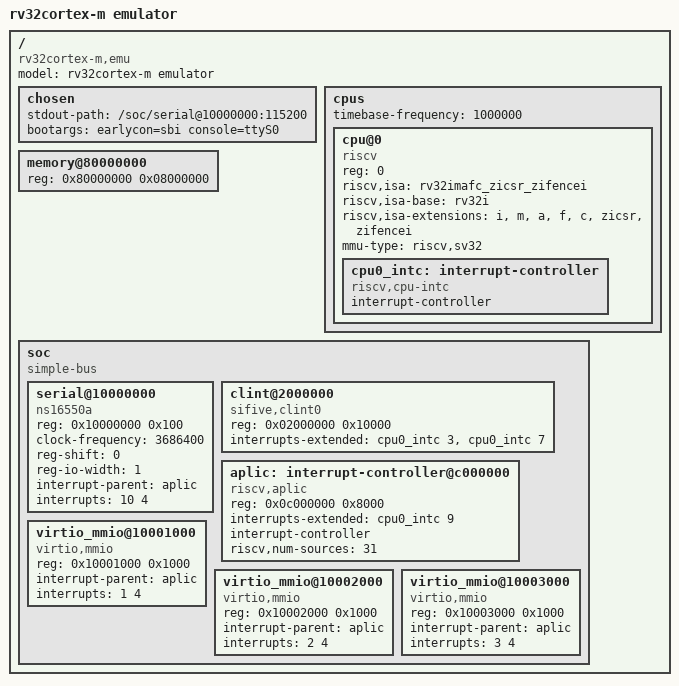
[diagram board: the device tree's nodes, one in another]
/dts-v1/;

/*
 * The machine this emulator presents to a supervisor payload.
 *
 * Why there is a device tree at all
 * --------------------------------
 * Every guest in this tree until now was compiled for these addresses.
 * OpenSBI and Linux are not: they are built once and told the shape of
 * the machine at boot, through a flattened tree whose address arrives in
 * a1. So this file *is* the machine description, and anything here that
 * disagrees with `include/emu/emu_memmap.h` or `include/rv32/rv_memmap.h`
 * is a bug that presents as firmware hanging with no output.
 *
 * The addresses are deliberately the QEMU `virt` ones, which is what the
 * emulator already chose independently: CLINT at 0x0200_0000, an
 * NS16550 at 0x1000_0000, RAM at 0x8000_0000. That means OpenSBI's
 * `generic` platform and an ordinary `rv32_defconfig` Linux need no
 * board support -- they read this and find a machine they know.
 *
 * Build it with:
 *   dtc -I dts -O dtb -o rv32-emu.dtb boot/rv32-emu.dts
 */

/ {
    #address-cells = <1>;
    #size-cells = <1>;
    compatible = "rv32cortex-m,emu";
    model = "rv32cortex-m emulator";

    chosen {
        /*
         * `stdout-path` is how OpenSBI and Linux find the console when
         * they are not told on the command line. Without it OpenSBI
         * comes up, works, and prints nothing -- which is
         * indistinguishable from not booting.
         */
        stdout-path = "/soc/serial@10000000:115200";
        /*
         * **The console goes through SBI, not the UART, and that is
         * deliberate for the first boot.**
         *
         * `earlycon=sbi` and `console=hvc0` are ecalls into OpenSBI,
         * which is already proven to reach this machine's NS16550. They
         * need no MMIO mapping, no interrupt and no PLIC -- and this
         * emulator has no PLIC, so an 8250 console would need the driver
         * to fall back to polling, which is one more thing that can be
         * wrong while the question is still whether the kernel boots at
         * all.
         *
         * **console=ttyS0, and hvc0 is the trap.** hvc0 works for printk
         * and does not work for userspace: it queues bytes and a kernel
         * thread (khvcd) pushes them out, so a write() from init
         * returns success and nothing is ever printed unless khvcd
         * gets scheduled. Every line of userspace output was lost that
         * way, with the only visible result a panic about killing init
         * -- which says nothing about whether userspace ran.
         *
         * ttyS0 is the NS16550 the emulator already provides, at
         * 0x10000000, and the 8250 driver binds to it from the node
         * below. Writes reach the host immediately because there is no
         * thread in between.
         *
         * earlycon stays on sbi: it runs before any driver is probed,
         * which is the whole point of it, and keep_bootcon leaves it
         * registered so nothing is lost at the handover.
         */
        bootargs = "earlycon=sbi console=ttyS0";
        /*
         * No `keep_bootcon`. It leaves the SBI boot console registered
         * beside ttyS0, so every line is printed twice -- which reads
         * as the emulator emitting each byte twice and was written down
         * here as exactly that before anyone removed the flag.
         */
    };

    cpus {
        #address-cells = <1>;
        #size-cells = <0>;

        /*
         * The tick the CLINT's mtime runs at, and it has to match what
         * the emulator actually increments mtime by.
         *
         * mtime is driven from the host's CLOCK_MONOTONIC in
         * microseconds -- or, on a Cortex-M board, from DWT CYCCNT --
         * so this is 1 MHz and it is a *real* frequency rather than a
         * ratio to pick.
         *
         * It used to advance by one per retired instruction, which made
         * a guest's clock and its progress unrelated quantities: dmesg
         * timestamps past 1500 seconds during driver init and watchdogs
         * firing on a machine running perfectly. Compensating here only
         * moved the problem -- at 100 MHz a timer interrupt programmed
         * for one jiffy needed a hundred times more instructions to
         * arrive, and the boot stalled instead.
         *
         * Keep this equal to the platform's board_clock_hz().
         */
        timebase-frequency = <1000000>;

        cpu@0 {
            device_type = "cpu";
            reg = <0>;
            status = "okay";
            compatible = "riscv";
            /*
             * What the core actually implements. F and C are there, and
             * the B extension, but a supervisor payload only cares about
             * IMA plus the privileged bits -- and naming an extension the
             * emulator lacks would have the kernel emit instructions that
             * trap.
             */
            riscv,isa = "rv32imafc_zicsr_zifencei";
            riscv,isa-base = "rv32i";
            riscv,isa-extensions = "i", "m", "a", "f", "c", "zicsr",
                                   "zifencei";
            mmu-type = "riscv,sv32";

            cpu0_intc: interrupt-controller {
                #interrupt-cells = <1>;
                interrupt-controller;
                compatible = "riscv,cpu-intc";
            };
        };
    };

    memory@80000000 {
        device_type = "memory";
        /*
         * Kept in step with the runner's --ram. 128 MiB is what a Linux
         * guest wants room for; a bare-metal one never reads this.
         */
        reg = <0x80000000 0x08000000>;
    };

    soc {
        #address-cells = <1>;
        #size-cells = <1>;
        compatible = "simple-bus";
        ranges;

        /*
         * The console. `clock-frequency` is what the driver divides to
         * get its baud rate; nothing in the emulator honours a divisor,
         * so the value only has to be self-consistent with the baud in
         * `bootargs`.
         */
        serial@10000000 {
            compatible = "ns16550a";
            reg = <0x10000000 0x100>;
            clock-frequency = <3686400>;
            reg-shift = <0>;
            reg-io-width = <1>;
            /*
             * **The interrupt is what makes userspace output work.**
             * Without it the 8250 driver binds anyway and the kernel's
             * own messages appear -- printk uses the polled console
             * path -- while every byte written by a *process* goes into
             * the tty buffer and waits for a transmit interrupt that
             * cannot arrive. write() returns success and userspace is
             * silent, which reads as the program not running.
             *
             * 10, above the virtio range: those are handed out from 1
             * in the order the emulator's options ask for, so a lower
             * number would collide as soon as a fourth device existed.
             * Nothing checks that this agrees with EMU_UART_IRQ in
             * emu_main.c -- two descriptions of one machine.
             */
            interrupt-parent = <&aplic>;
            interrupts = <10 4>;
            status = "okay";
        };

        /*
         * CLINT: software interrupts at the base, mtimecmp at +0x4000 and
         * mtime at +0xBFF8, which is the legacy SiFive layout the
         * emulator implements and every RISC-V supervisor expects.
         */
        clint@2000000 {
            compatible = "sifive,clint0", "riscv,clint0";
            reg = <0x02000000 0x10000>;
            interrupts-extended = <&cpu0_intc 3 &cpu0_intc 7>;
        };

        /*
         * APLIC, in **direct mode**.
         *
         * Direct because MSI mode needs an IMSIC and the AIA CSRs, and
         * this emulator implements neither -- which the absence of
         * `msi-parent` is what states. A node with one would be probed
         * as MSI and fail at a layer that does not mention the tree.
         *
         * `interrupts-extended = <&cpu0_intc 9>` is the supervisor
         * external interrupt, and it is the line this whole node hangs
         * on: the emulator's APLIC delivers to M-mode by default and
         * must be told otherwise with **--supervisor**. The two have to
         * agree and nothing checks that they do -- they are two
         * descriptions of one machine, and disagreeing is silent. Every
         * register reads correctly and the interrupt arrives at a
         * privilege Linux is not running at, so a driver waits for ever
         * on a queue that already completed.
         *
         * 9 is S-mode external; 11 would be M-mode, for a tree
         * describing a machine with no supervisor.
         */
        aplic: interrupt-controller@c000000 {
            compatible = "riscv,aplic";
            reg = <0x0c000000 0x8000>;
            interrupts-extended = <&cpu0_intc 9>;
            interrupt-controller;
            #interrupt-cells = <2>;
            riscv,num-sources = <31>;
        };

        /*
         * virtio-mmio, at the addresses emu_main.c hands the devices:
         * 0x1000_1000 upwards, 0x1000 apart, interrupts from 1. That is
         * the `virt` machines' layout, so a tree written for one of
         * those needs the fewest changes.
         *
         * The second cell of `interrupts` is the trigger type, and 4 is
         * level-high -- which is what virtio-mmio is: the device holds
         * its line up until the guest writes InterruptACK. Declaring it
         * edge would work until two completions arrived close together,
         * which is the kind of bug that appears only under load.
         *
         * The emulator fills these in the order the options ask for
         * them -- `--virtio-input` gives a keyboard then a mouse, then
         * `--9p` -- so which node is which follows the command line
         * rather than the tree. That is fine for Linux, which reads the
         * device id out of each and binds a driver accordingly; it is
         * not fine for anything that assumes a node's purpose from its
         * address.
         *
         * One node per device the emulator was asked for. A node with
         * no device behind it reads all-ones and is skipped by the
         * driver, so extras are harmless -- but a *device* with no node
         * is invisible, which is the direction that costs time.
         */
        virtio_mmio@10001000 {
            compatible = "virtio,mmio";
            reg = <0x10001000 0x1000>;
            interrupt-parent = <&aplic>;
            interrupts = <1 4>;
        };

        virtio_mmio@10002000 {
            compatible = "virtio,mmio";
            reg = <0x10002000 0x1000>;
            interrupt-parent = <&aplic>;
            interrupts = <2 4>;
        };

        virtio_mmio@10003000 {
            compatible = "virtio,mmio";
            reg = <0x10003000 0x1000>;
            interrupt-parent = <&aplic>;
            interrupts = <3 4>;
        };
    };
};
